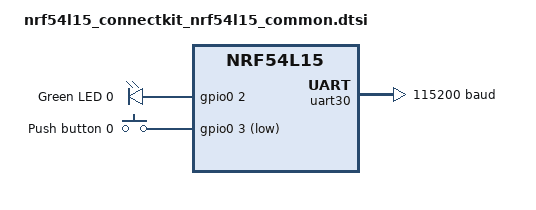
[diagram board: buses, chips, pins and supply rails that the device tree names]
/*
 * Copyright (c) 2016-2025 Makerdiary <https://makerdiary.com>
 *
 * SPDX-License-Identifier: Apache-2.0
 */

#include "nrf54l15_connectkit_nrf54l15-pinctrl.dtsi"

/ {
	leds {
		compatible = "gpio-leds";
		led0: led_0 {
			gpios = <&gpio0 2 GPIO_ACTIVE_HIGH>;
			label = "Green LED 0";
		};
	};

	buttons {
		compatible = "gpio-keys";
		button0: button_0 {
			gpios = <&gpio0 3 (GPIO_PULL_UP | GPIO_ACTIVE_LOW)>;
			label = "Push button 0";
			zephyr,code = <INPUT_KEY_0>;
		};
	};

	aliases {
		led0 = &led0;
		sw0 = &button0;
		watchdog0 = &wdt31;
	};
};

&uart30 {
	current-speed = <115200>;
	pinctrl-0 = <&uart30_default>;
	pinctrl-1 = <&uart30_sleep>;
	pinctrl-names = "default", "sleep";
};
